# D1H.pdf register map
Vendor: Allwinner; Series: D1H.pdf; File version: 0.1
CPU: XuanTie C906 RISC-V CPU 0, little endian, MPU, FPU, double-precision FPU, 0 interrupt priority bits
Registers are 32-bit, read-write, reset 0x0 unless marked. A register's access mark holds for its fields unless they carry their own. Offsets are from the block's base; [hi:lo] are bit positions; {n}, {i} and the like mark numbered series; 'fields as' and 'values as' point back to an identical list.

## GPIO
Base 0x02000000
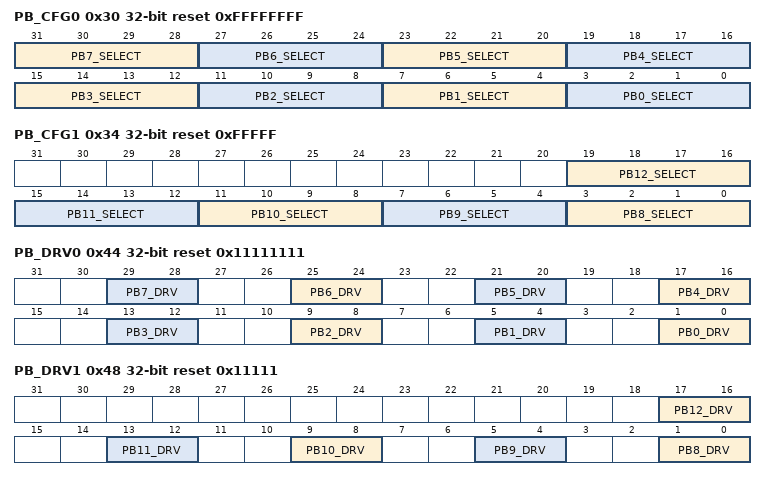
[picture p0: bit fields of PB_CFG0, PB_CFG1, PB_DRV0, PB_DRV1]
0x30 PB_CFG0 reset 0xFFFFFFFF — PB Configure Register 0
  [31:28] PB7_SELECT — PB7 Select 0000:Input 0001:Output 0010:LCD0-D17 0011:I2S2-MCLK 0100:TWI3-SDA 0101:IR-RX 0110:LCD0-D23 0111:UART3-RX 1000:CPUBIST1 1001:Reserved 1110:PB-EINT7 1111:IO Disable
  [27:24] PB6_SELECT — PB6 Select 0000:Input 0001:Output 0010:LCD0-D16 0011:I2S2-LRCK 0100:TWI3-SCK 0101:PWM1 0110:LCD0-D22 0111:UART3-TX 1000:CPUBIST0 1001:Reserved 1110:PB-EINT6 1111:IO Disable
  [23:20] PB5_SELECT — PB5 Select 0000:Input 0001:Output 0010:LCD0-D9 0011:I2S2-BCLK 0100:TWI1-SDA 0101:PWM0 0110:LCD0-D21 0111:UART5-RX 1000:Reserved 1001:Reserved 1110:PB-EINT5 1111:IO Disable
  [19:16] PB4_SELECT — PB4 Select 0000:Input 0001:Output 0010:LCD0-D8 0011:I2S2-DOUT0 0100:TWI1-SCK 0101:I2S2-DIN1 0110:LCD0-D20 0111:UART5-TX 1000:Reserved 1001:Reserved 1110:PB-EINT4 1111:IO Disable
  [15:12] PB3_SELECT — PB3 Select 0000:Input 0001:Output 0010:LCD0-D1 0011:I2S2-DOUT1 0100:TWI0-SCK 0101:I2S2-DIN0 0110:LCD0-D19 0111:UART4-RX 1000:Reserved 1001:Reserved 1110:PB-EINT3 1111:IO Disable
  [11:8] PB2_SELECT — PB2 Select 0000:Input 0001:Output 0010:LCD0-D0 0011:I2S2-DOUT2 0100:TWI0-SDA 0101:I2S2-DIN2 0110:LCD0-D18 0111:UART4-TX 1000:Reserved 1001:Reserved 1110:PB-EINT2 1111:IO Disable
  [7:4] PB1_SELECT — PB1 Select 0000:Input 0001:Output 0010:PWM4 0011:I2S2-DOUT3 0100:TWI2-SDA 0101:I2S2-DIN3 0110:UART0-RX 0111:UART2-RX 1000:IR-RX 1001:Reserved 1110:PB-EINT1 1111:IO Disable
  [3:0] PB0_SELECT — PB0 Select 0000:Input 0001:Output 0010:PWM3 0011:IR-TX 0100:TWI2-SCK 0101:SPI1-WP/DBI-TE 0110:UART0-TX 0111:UART2-TX 1000:OWA-OUT 1001:Reserved 1110:PB-EINT0 1111:IO Disable
0x34 PB_CFG1 reset 0xFFFFF — PB Configure Register 1
  [19:16] PB12_SELECT — PB12 Select 0000:Input 0001:Output 0010:DMIC-CLK 0011:PWM0 0100: Reserved 0101:SPI1-CS/DBI-CSX 0110:CLK-FANOUT2 0111:IR-RX 1000:Reserved 1001:Reserved 1110:PB-EINT12 1111:IO Disable
    5=SPI1_minus_CS_slash_DBI_minus_CSX (SPI1-CS/DBI-CSX); 6=CLK_minus_FANOUT2 (CLK-FANOUT2); 7=IR_minus_RX (IR-RX); 14=PB_minus_EINT12 (PB-EINT12); 15=IO (IO Disable)
  [15:12] PB11_SELECT — PB11 Select 0000:Input 0001:Output 0010:DMIC-DATA0 0011:PWM2 0100:TWI0-SDA 0101:SPI1-CLK/DBI-SCLK 0110:CLK-FANOUT1 0111:UART1-CTS 1000:Reserved 1001:Reserved 1110:PB-EINT11 1111:IO Disable
  [11:8] PB10_SELECT — PB10 Select 0000:Input 0001:Output 0010:DMIC-DATA1 0011:PWM7 0100:TWI0-SCK 0101:SPI1-MOSI/DBI-SDO 0110:CLK-FANOUT0 0111:UART1-RTS 1000:Reserved 1001:Reserved 1110:PB-EINT10 1111:IO Disable
  [7:4] PB9_SELECT — PB9 Select 0000:Input 0001:Output 0010:DMIC-DATA2 0011:PWM6 0100:TWI2-SDA 0101:SPI1-MISO/DBI-SDI/DBI-TE/DBI-DCX 0110:UART0-RX 0111:UART1-RX 1000:Reserved 1001:Reserved 1110:PB-EINT9 1111:IO Disable
  [3:0] PB8_SELECT — PB8 Select 0000:Input 0001:Output 0010:DMIC-DATA3 0011:PWM5 0100:TWI2-SCK 0101:SPI1-HOLD/DBI-DCX/DBI-WRX 0110:UART0-TX 0111:UART1-TX 1000:Reserved 1001:Reserved 1110:PB-EINT8 1111:IO Disable
0x40 PB_DAT — PB Data Register
  [12:0] PB_DAT — If the port is configured as the input function, the corresponding bit is the pin state. If the port is configured as the output function, the pin state is the same as the corresponding bit. The read bit value is the value set up by software. If the port is configured as a functional pin, the undefined value will be read.
0x44 PB_DRV0 reset 0x11111111 — PB Multi_Driving Register 0
  [all] fields
    {v}=Level_{v} (v=0..3)
  [4n+1:4n] PB{n}_DRV (n=0..7) — PB{n} Multi_Driving Select 00: Level 0 01: Level 1 10: Level 2 11: Level 3
0x48 PB_DRV1 reset 0x11111 — PB Multi_Driving Register 1
  [all] fields
    {v}=Level_{v} (v=0..3)
  [4n-31:4n-32] PB{n}_DRV (n=8..12) — PB{n} Multi_Driving Select 00: Level 0 01: Level 1 10: Level 2 11: Level 3
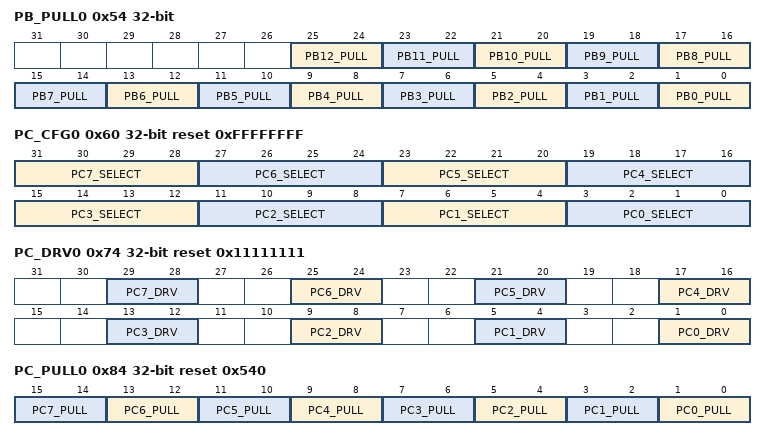
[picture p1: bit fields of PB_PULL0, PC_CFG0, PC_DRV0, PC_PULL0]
0x54 PB_PULL0 — PB Pull Register 0
  [all] fields
    0=Pull_up_slash_down_disable (Pull_up/down disable); 1=Pull_up; 2=Pull_down
  [2n+1:2n] PB{n}_PULL (n=0..12) — PB{n} Pull_up or down Select 00: Pull_up/down disable 01: Pull_up 10: Pull_down 11: Reserved
0x60 PC_CFG0 reset 0xFFFFFFFF — PC Configure Register 0
  [31:28] PC7_SELECT — PC7 Select 0000:Input 0001:Output 0010:SPI0-HOLD 0011:SDC2-D3 0100:UART3-RX 0101:TWI3-SDA 0110:TCON-TRIG 0111:Reserved 1000:Reserved 1001:Reserved 1110:PC-EINT7 1111:IO Disable
  [27:24] PC6_SELECT — PC6 Select 0000:Input 0001:Output 0010:SPI0-WP 0011:SDC2-D0 0100:UART3-TX 0101:TWI3-SCK 0110:DBG-CLK 0111:Reserved 1000:Reserved 1001:Reserved 1110:PC-EINT6 1111:IO Disable
  [23:20] PC5_SELECT — PC5 Select 0000:Input 0001:Output 0010:SPI0-MISO 0011:SDC2-D1 0100:BOOT-SEL1 0101:Reserved 0110:Reserved 0111:Reserved 1000:Reserved 1001:Reserved 1110:PC-EINT5 1111:IO Disable
  [19:16] PC4_SELECT — PC4 Select 0000:Input 0001:Output 0010:SPI0-MOSI 0011:SDC2-D2 0100:BOOT-SEL0 0101:Reserved 0110:Reserved 0111:Reserved 1000:Reserved 1001:Reserved 1110:PC-EINT4 1111:IO Disable
  [15:12] PC3_SELECT — PC3 Select 0000:Input 0001:Output 0010:SPI0-CS0 0011:SDC2-CMD 0100:Reserved 0101:Reserved 0110:Reserved 0111:Reserved 1000:Reserved 1001:Reserved 1110:PC-EINT3 1111:IO Disable
  [11:8] PC2_SELECT — PC2 Select 0000:Input 0001:Output 0010:SPI0-CLK 0011:SDC2-CLK 0100:Reserved 0101:Reserved 0110:Reserved 0111:Reserved 1000:Reserved 1001:Reserved 1110:PC-EINT2 1111:IO Disable
  [7:4] PC1_SELECT — PC1 Select. 0000:Input 0001:Output 0010:UART2-RX 0011:TWI2-SDA 0100:Reserved 0101:Reserved 0110:Reserved 0111:Reserved 1000:Reserved 1001:Reserved 1110:PC-EINT1 1111:IO Disable
  [3:0] PC0_SELECT — PC0 Select 0000:Input 0001:Output 0010:UART2-TX 0011:TWI2-SCK 0100:LEDC-DO 0101:Reserved 0110:Reserved 0111:Reserved 1000:Reserved 1001:Reserved 1110:PC-EINT0 1111:IO Disable
0x70 PC_DAT — PC Data Register
  [7:0] PC_DAT — If the port is configured as the input function, the corresponding bit is the pin state. If the port is configured as the output function, the pin state is the same as the corresponding bit. The read bit value is the value set up by software. If the port is configured as a functional pin, the undefined value will be read.
0x74 PC_DRV0 reset 0x11111111 — PC Multi_Driving Register 0
  [all] fields
    {v}=Level_{v} (v=0..3)
  [4n+1:4n] PC{n}_DRV (n=0..7) — PC{n} Multi_Driving Select 00: Level 0 01: Level 1 10: Level 2 11: Level 3
0x84 PC_PULL0 reset 0x540 — PC Pull Register 0
  [all] fields
    values as the fields of PB_PULL0
  [2n+1:2n] PC{n}_PULL (n=0..7) — PC{n} Pull_up/down Select 00: Pull_up/down disable 01: Pull_up 10: Pull_down 11: Reserved
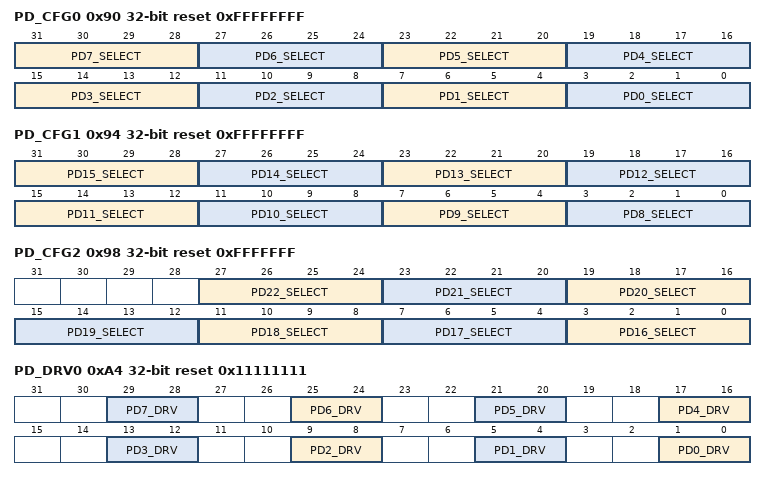
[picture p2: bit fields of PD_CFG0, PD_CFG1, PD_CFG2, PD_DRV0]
0x90 PD_CFG0 reset 0xFFFFFFFF — PD Configure Register 0
  [31:28] PD7_SELECT — PD7 Select 0000:Input 0001:Output 0010:LCD0-D11 0011:LVDS0-CKN 0100:DSI-D2N 0101:UART4-TX 0110:Reserved 0111:Reserved 1000:Reserved 1001:Reserved 1110:PD-EINT7 1111:IO Disable
  [27:24] PD6_SELECT — PD6 Select 0000:Input 0001:Output 0010:LCD0-D10 0011:LVDS0-CKP 0100:DSI-D2P 0101:UART5-RX 0110:Reserved 0111:Reserved 1000:Reserved 1001:Reserved 1110:PD-EINT6 1111:IO Disable
  [23:20] PD5_SELECT — PD5 Select 0000:Input 0001:Output 0010:LCD0-D7 0011:LVDS0-V2N 0100:DSI-CKN 0101:UART5-TX 0110:Reserved 0111:Reserved 1000:Reserved 1001:Reserved 1110:PD-EINT5 1111:IO Disable
  [19:16] PD4_SELECT — PD4 Select 0000:Input 0001:Output 0010:LCD0-D6 0011:LVDS0-V2P 0100:DSI-CKP 0101:UART2-CTS 0110:Reserved 0111:Reserved 1000:Reserved 1001:Reserved 1110:PD-EINT4 1111:IO Disable
  [15:12] PD3_SELECT — PD3 Select 0000:Input 0001:Output 0010:LCD0-D5 0011:LVDS0-V1N 0100:DSI-D1N 0101:UART2-RTS 0110:Reserved 0111:Reserved 1000:Reserved 1001:Reserved 1110:PD-EINT3 1111:IO Disable
  [11:8] PD2_SELECT — PD2 Select 0000:Input 0001:Output 0010:LCD0-D4 0011:LVDS0-V1P 0100:DSI-D1P 0101:UART2-RX 0110:Reserved 0111:Reserved 1000:Reserved 1001:Reserved 1110:PD-EINT2 1111:IO Disable
  [7:4] PD1_SELECT — PD1 Select 0000:Input 0001:Output 0010:LCD0-D3 0011:LVDS0-V0N 0100:DSI-D0N 0101:UART2-TX 0110:Reserved 0111:Reserved 1000:Reserved 1001:Reserved 1110:PD-EINT1 1111:IO Disable
  [3:0] PD0_SELECT — PD0 Select 0000:Input 0001:Output 0010:LCD0-D2 0011:LVDS0-V0P 0100:DSI-D0P 0101:TWI0-SCK 0110:Reserved 0111:Reserved 1000:Reserved 1001:Reserved 1110:PD-EINT0 1111:IO Disable
0x94 PD_CFG1 reset 0xFFFFFFFF — PD Configure Register 1
  [31:28] PD15_SELECT — PD15 Select 0000:Input 0001:Output 0010:LCD0-D21 0011:LVDS1-V2N 0100:SPI1-WP/DBI-TE 0101:IR-RX 0110:Reserved 0111:Reserved 1000:Reserved 1001:Reserved 1110:PD-EINT15 1111:IO Disable
  [27:24] PD14_SELECT — PD14 Select 0000:Input 0001:Output 0010:LCD0-D20 0011:LVDS1-V2P 0100:SPI1-HOLD/DBI-DCX/DBI-WRX 0101:UART3-CTS 0110:Reserved 0111:Reserved 1000:Reserved 1001:Reserved 1110:PD-EINT14 1111:IO Disable
  [23:20] PD13_SELECT — PD13 Select 0000:Input 0001:Output 0010:LCD0-D19 0011:LVDS1-V1N 0100:SPI1-MISO/DBI-SDI/DBI-TE/DBI-DCX 0101:UART3-RTS 0110:Reserved 0111:Reserved 1000:Reserved 1001:Reserved 1110:PD-EINT13 1111:IO Disable
  [19:16] PD12_SELECT — PD12 Select 0000:Input 0001:Output 0010:LCD0-D18 0011:LVDS1-V1P 0100:SPI1-MOSI/DBI-SDO 0101:TWI0-SDA 0110:Reserved 0111:Reserved 1000:Reserved 1001:Reserved 1110:PD-EINT12 1111:IO Disable
  [15:12] PD11_SELECT — PD11 Select 0000:Input 0001:Output 0010:LCD0-D15 0011:LVDS1-V0N 0100:SPI1-CLK/DBI-SCLK 0101:UART3-RX 0110:Reserved 0111:Reserved 1000:Reserved 1001:Reserved 1110:PD-EINT11 1111:IO Disable
  [11:8] PD10_SELECT — PD10 Select 0000:Input 0001:Output 0010:LCD0-D14 0011:LVDS1-V0P 0100:SPI1-CS/DBI-CSX 0101:UART3-TX 0110:Reserved 0111:Reserved 1000:Reserved 1001:Reserved 1110:PD-EINT10 1111:IO Disable
  [7:4] PD9_SELECT — PD9 Select 0000:Input 0001:Output 0010:LCD0-D13 0011:LVDS0-V3N 0100:DSI-D3N 0101:PWM6 0110:Reserved 0111:Reserved 1000:Reserved 1001:Reserved 1110:PD-EINT9 1111:IO Disable
  [3:0] PD8_SELECT — PD8 Select 0000:Input 0001:Output 0010:LCD0-D12 0011:LVDS0-V3P 0100:DSI-D3P 0101:UART4-RX 0110:Reserved 0111:Reserved 1000:Reserved 1001:Reserved 1110:PD-EINT8 1111:IO Disable
0x98 PD_CFG2 reset 0xFFFFFFF — PD Configure Register 2
  [27:24] PD22_SELECT — PD22 Select 0000:Input 0001:Output 0010:OWA-OUT 0011:IR-RX 0100:UART1-RX 0101:PWM7 0110:Reserved 0111:Reserved 1000:Reserved 1001:Reserved 1110:PD-EINT22 1111:IO Disable
  [23:20] PD21_SELECT — PD21 Select 0000:Input 0001:Output 0010:LCD0-VSYNC 0011:TWI2-SDA 0100:UART1-TX 0101:PWM5 0110:Reserved 0111:Reserved 1000:Reserved 1001:Reserved 1110:PD-EINT21 1111:IO Disable
  [19:16] PD20_SELECT — PD20 Select 0000:Input 0001:Output 0010:LCD0-HSYNC 0011:TWI2-SCK 0100:DMIC-CLK 0101:PWM4 0110:Reserved 0111:Reserved 1000:Reserved 1001:Reserved 1110:PD-EINT20 1111:IO Disable
  [15:12] PD19_SELECT — PD19 Select 0000:Input 0001:Output 0010:LCD0-DE 0011:LVDS1-V3N 0100:DMIC-DATA0 0101:PWM3 0110:Reserved 0111:Reserved 1000:Reserved 1001:Reserved 1110:PD-EINT19 1111:IO Disable
  [11:8] PD18_SELECT — PD18 Select 0000:Input 0001:Output 0010:LCD0-CLK 0011:LVDS1-V3P 0100:DMIC-DATA1 0101:PWM2 0110:Reserved 0111:Reserved 1000:Reserved 1001:Reserved 1110:PD-EINT18 1111:IO Disable
  [7:4] PD17_SELECT — PD17 Select. 0000:Input 0001:Output 0010:LCD0-D23 0011:LVDS1-CKN 0100:DMIC-DATA2 0101:PWM1 0110:Reserved 0111:Reserved 1000:Reserved 1001:Reserved 1110:PD-EINT17 1111:IO Disable
  [3:0] PD16_SELECT — PD16 Select 0000:Input 0001:Output 0010:LCD0-D22 0011:LVDS1-CKP 0100:DMIC-DATA3 0101:PWM0 0110:Reserved 0111:Reserved 1000:Reserved 1001:Reserved 1110:PD-EINT16 1111:IO Disable
0xA0 PD_DAT — PD Data Register
  [22:0] PD_DAT — PD Data If the port is configured as the input function, the corresponding bit is the pin state. If the port is configured as the output function, the pin state is the same as the corresponding bit. The read bit value is the value set up by software. If the port is configured as a functional pin, the undefined value will be read.
0xA4 PD_DRV0 reset 0x11111111 — PD Multi_Driving Register 0
  [all] fields
    {v}=Level_{v} (v=0..3)
  [4n+1:4n] PD{n}_DRV (n=0..7) — PD{n} Multi_Driving Select. 00: Level 0 01: Level 1 10: Level 2 11: Level 3
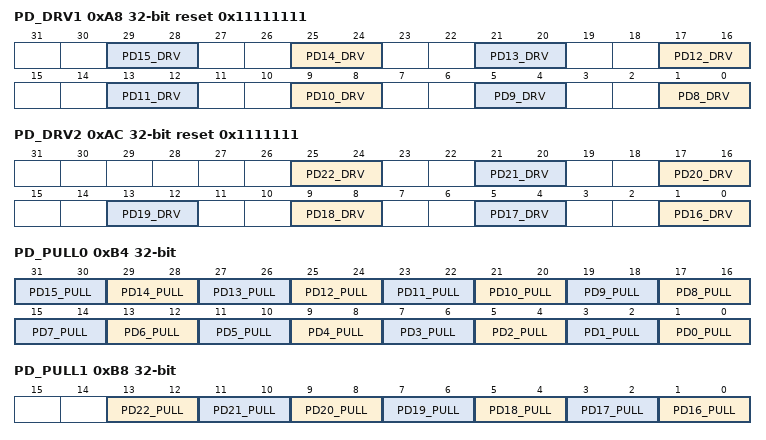
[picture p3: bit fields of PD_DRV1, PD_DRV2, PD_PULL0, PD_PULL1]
0xA8 PD_DRV1 reset 0x11111111 — PD Multi_Driving Register 1
  [all] fields
    {v}=Level_{v} (v=0..3)
  [4n-31:4n-32] PD{n}_DRV (n=8..15) — PD{n} Multi_Driving Select. 00: Level 0 01: Level 1 10: Level 2 11: Level 3
0xAC PD_DRV2 reset 0x1111111 — PD Multi_Driving Register 2
  [all] fields
    {v}=Level_{v} (v=0..3)
  [4n-63:4n-64] PD{n}_DRV (n=16..22) — PD{n} Multi_Driving Select. 00: Level 0 01: Level 1 10: Level 2 11: Level 3
0xB4 PD_PULL0 — PD Pull Register 0
  [all] fields
    values as the fields of PB_PULL0
  [2n+1:2n] PD{n}_PULL (n=0..15) — PD{n} Pull_up or down Select. 00: Pull_up/down disable 01: Pull_up 10: Pull_down 11: Reserved
0xB8 PD_PULL1 — PD Pull Register 1
  [all] fields
    values as the fields of PB_PULL0
  [2n-31:2n-32] PD{n}_PULL (n=16..22) — PD{n} Pull_up or down Select. 00: Pull_up/down disable 01: Pull_up 10: Pull_down 11: Reserved
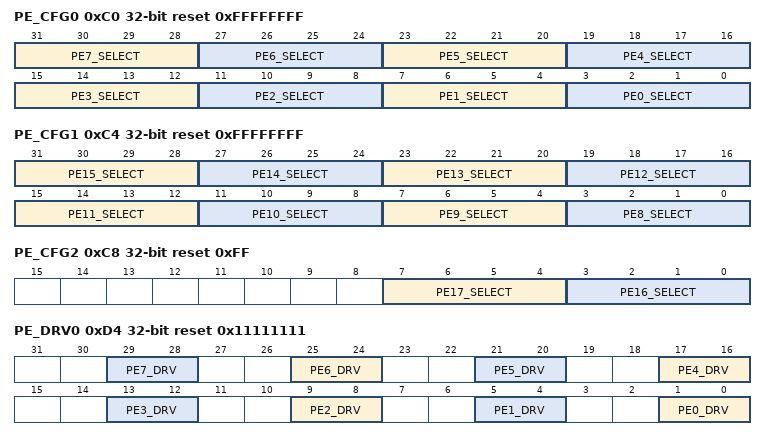
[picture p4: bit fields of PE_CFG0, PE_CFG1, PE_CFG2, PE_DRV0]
0xC0 PE_CFG0 reset 0xFFFFFFFF — PE Configure Register 0
  [31:28] PE7_SELECT — PE7 Select 0000:Input 0001:Output 0010:NCSI0-D3 0011:UART5-RX 0100:TWI3-SDA 0101:OWA-OUT 0110:D-JTAG-CK 0111:R-JTAG-CK 1000:RGMII-CLKIN/RMII-RXER 1001:Reserved 1110:PE-EINT7 1111:IO Disable
  [27:24] PE6_SELECT — PE6 Select 0000:Input 0001:Output 0010:NCSI0-D2 0011:UART5-TX 0100:TWI3-SCK 0101: Reserved 0110:D-JTAG-DO 0111:R-JTAG-DO 1000:RMII-TXCTRL/RMII-TXEN 1001:Reserved 1110:PE-EINT6 1111:IO Disable
  [23:20] PE5_SELECT — PE5 Select 0000:Input 0001:Output 0010:NCSI0-D1 0011:UART4-RX 0100:TWI2-SDA 0101:LEDC-DO 0110:D-JTAG-DI 0111:R-JTAG-DI 1000:RGMII-TXD1/RMII-TXD1 1001:Reserved 1110:PE-EINT5 1111:IO Disable
  [19:16] PE4_SELECT — PE4 Select 0000:Input 0001:Output 0010:NCSI0-D0 0011:UART4-TX 0100:TWI2-SCK 0101:CLK-FANOUT2 0110:D-JTAG-MS 0111:R-JTAG-MS 1000:RGMII-TXD0/RMII-TXD0 1001:Reserved 1110:PE-EINT4 1111:IO Disable
  [15:12] PE3_SELECT — PE3 Select 0000:Input 0001:Output 0010:NCSI0-MCLK 0011:UART2-RX 0100:TWI0-SDA 0101:CLK-FANOUT1 0110:UART0-RX 0111:Reserved 1000:RGMII-TXCK/RMII-TXCK 1001:Reserved 1110:PE-EINT3 1111:IO Disable
  [11:8] PE2_SELECT — PE2 Select 0000:Input 0001:Output 0010:NCSI0-PCLK 0011:UART2-TX 0100:TWI0-SCK 0101:CLK-FANOUT0 0110:UART0-TX 0111:Reserved 1000:RGMII-RXD1/RMII-RXD1 1001:Reserved 1110:PE-EINT2 1111:IO Disable
  [7:4] PE1_SELECT — PE1 Select 0000:Input 0001:Output 0010:NCSI0-VSYNC 0011:UART2-CTS 0100:TWI1-SDA 0101:LCD0-VSYNC 0110:Reserved 0111:Reserved 1000:RGMII-RXD0/RMII-RXD0 1001:Reserved 1110:PE-EINT1 1111:IO Disable
  [3:0] PE0_SELECT — PE0 Select 0000:Input 0001:Output 0010:NCSI0-HSYNC 0011:UART2-RTS 0100:TWI1-SCK 0101:LCD0-HSYNC 0110:Reserved 0111:Reserved 1000:RGMII-RXCTRL/RMII-CRS-DV 1001:Reserved 1110:PE-EINT0 1111:IO Disable
0xC4 PE_CFG1 reset 0xFFFFFFFF — PE Configure Register 1
  [31:28] PE15_SELECT — PE15 Select 0000:Input 0001:Output 0010:TWI1-SDA 0011:D-JTAG-DI 0100:PWM6 0101:I2S0-LRCK 0110:DMIC-DATA1 0111:Reserved 1000:RGMII-RXCK 1001:Reserved 1110:PE-EINT15 1111:IO Disable
  [27:24] PE14_SELECT — PE14 Select 0000:Input 0001:Output 0010:TWI1-SCK 0011:D-JTAG-MS 0100:I2S0-DOUT1 0101:I2S0-DIN0 0110:DMIC-DATA2 0111:Reserved 1000:RGMII-RXD3 1001:Reserved 1110:PE-EINT14 1111:IO Disable
  [23:20] PE13_SELECT — PE13 Select 0000:Input 0001:Output 0010:TWI2-SDA 0011:PWM5 0100:I2S0-DOUT0 0101:I2S0-DIN1 0110:DMIC-DATA3 0111:Reserved 1000:RGMII-RXD2 1001:Reserved 1110:PE-EINT13 1111:IO Disable
  [19:16] PE12_SELECT — PE12 Select 0000:Input 0001:Output 0010:TWI2-SCK 0011:NCSI0-FIELD 0100:I2S0-DOUT2 0101:I2S0-DIN2 0110:Reserved 0111:Reserved 1000:RGMII-TXD3 1001:Reserved 1110:PE-EINT12 1111:IO Disable
  [15:12] PE11_SELECT — PE11 Select 0000:Input 0001:Output 0010:NCSI0-D7 0011:UART1-RX 0100:I2S0-DOUT3 0101:I2S0-DIN3 0110:Reserved 0111:Reserved 1000:RGMII-TXD2 1001:Reserved 1110:PE-EINT11 1111:IO Disable
  [11:8] PE10_SELECT — PE10 Select 0000:Input 0001:Output 0010:NCSI0-D6 0011:UART1-TX 0100:PWM4 0101:IR-RX 0110:Reserved 0111:Reserved 1000:EPHY-25M 1001:Reserved 1110:PE-EINT10 1111:IO Disable
  [7:4] PE9_SELECT — PE9 Select 0000:Input 0001:Output 0010:NCSI0-D5 0011:UART1-CTS 0100:PWM3 0101:UART3-RX 0110:Reserved 0111:Reserved 1000:MDIO 1001:Reserved 1110:PE-EINT9 1111:IO Disable
  [3:0] PE8_SELECT — PE8 Select 0000:Input 0001:Output 0010:NCSI0-D4 0011:UART1-RTS 0100:PWM2 0101:UART3-TX 0110:Reserved 0111:Reserved 1000:MDC 1001:Reserved 1110:PE-EINT8 1111:IO Disable
0xC8 PE_CFG2 reset 0xFF
  [7:4] PE17_SELECT — PE17 Select 0000:Input 0001:Output 0010:TWI3-SDA 0011:D-JTAG-CK 0100:IR-TX 0101:I2S0-MCLK 0110:DMIC-CLK 0111:Reserved 1000:Reserved 1001:Reserved 1110:PE-EINT17 1111:IO Disable
  [3:0] PE16_SELECT — PE16 Select 0000:Input 0001:Output 0010:TWI3-SCK 0011:D-JTAG-DO 0100:PWM7 0101:I2S0-BCLK 0110:DMIC-DATA0 0111:Reserved 1000:Reserved 1001:Reserved 1110:PE-EINT16 1111:IO Disable
0xD0 PE_DAT — PE Data Register
  [17:0] PE_DAT — PE Data If the port is configured as input, the corresponding bit is the pin state. If the port is configured as output, the pin state is the same as the corresponding bit. The read bit value is the value setup by software. If the port is configured as functional pin, the undefined value will be read.
0xD4 PE_DRV0 reset 0x11111111 — PE Multi_Driving Register 0
  [all] fields
    {v}=Level_{v} (v=0..3)
  [4n+1:4n] PE{n}_DRV (n=0..7) — PE{n} Multi_Driving Select 00: Level 0 01: Level 1 10: Level 2 11: Level 3
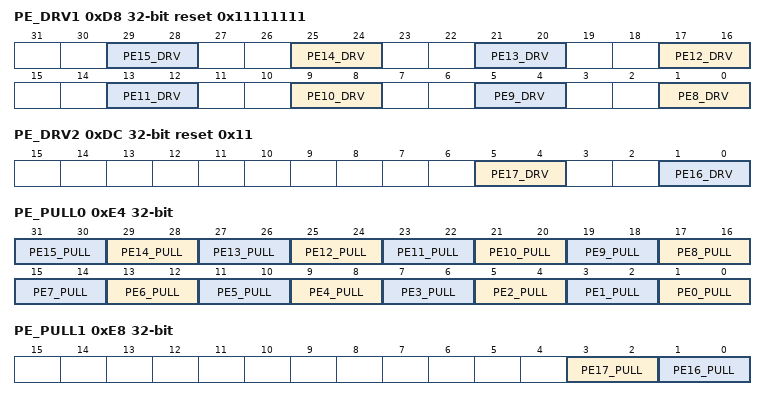
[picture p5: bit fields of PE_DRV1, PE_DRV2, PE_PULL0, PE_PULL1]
0xD8 PE_DRV1 reset 0x11111111 — PE Multi_Driving Register 1
  [all] fields
    {v}=Level_{v} (v=0..3)
  [4n-31:4n-32] PE{n}_DRV (n=8..15) — PE{n} Multi_Driving Select 00: Level 0 01: Level 1 10: Level 2 11: Level 3
0xDC PE_DRV2 reset 0x11
  [5:4] PE17_DRV — PE17 Multi_Driving Select 00: Level 0 01: Level 1 10: Level 2 11: Level 3
    {v}=Level_{v} (v=0..3)
  [1:0] PE16_DRV — PE16 Multi_Driving Select 00: Level 0 01: Level 1 10: Level 2 11: Level 3
    {v}=Level_{v} (v=0..3)
0xE4 PE_PULL0 — PE Pull Register 0
  [all] fields
    values as the fields of PB_PULL0
  [2n+1:2n] PE{n}_PULL (n=0..15) — PE{n} Pull_up or down Select 00: Pull_up/down disable 01: Pull_up 10: Pull_down 11: Reserved
0xE8 PE_PULL1
  [3:2] PE17_PULL — PE17 Pull_up or down Select 00: Pull_up/down disable 01: Pull_up 10: Pull_down 11: Reserved
    values as the fields of PB_PULL0
  [1:0] PE16_PULL — PE16 Pull_up or down Select 00: Pull_up/down disable 01: Pull_up 10: Pull_down 11: Reserved
    values as the fields of PB_PULL0
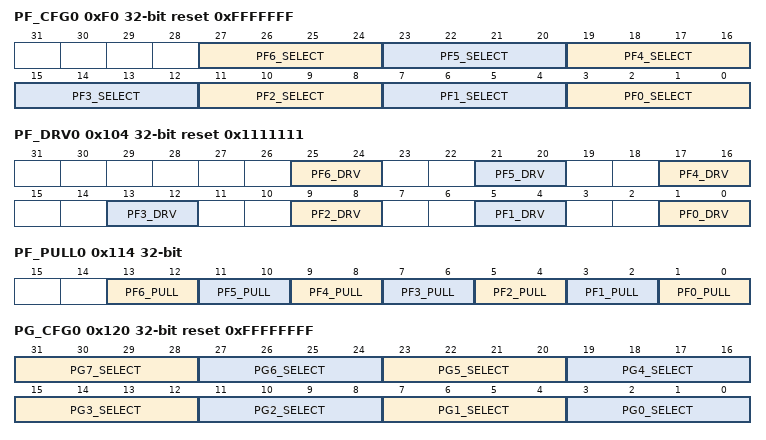
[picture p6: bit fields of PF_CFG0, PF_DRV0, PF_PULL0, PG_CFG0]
0xF0 PF_CFG0 reset 0xFFFFFFF — PF Configure Register 0
  [27:24] PF6_SELECT — PF6 Select 0000:Input 0001:Output 0010:Reserved 0011:OWA-OUT 0100:IR-RX 0101:I2S2-MCLK 0110:PWM5 0111:Reserved 1000:Reserved 1001:Reserved 1110:PF-EINT6 1111:IO Disable
  [23:20] PF5_SELECT — PF5 Select 0000:Input 0001:Output 0010:SDC0-D2 0011:Reserved 0100:R-JTAG-CK 0101:I2S2-LRCK 0110:Reserved 0111:Reserved 1000:Reserved 1001:Reserved 1110:PF-EINT5 1111:IO Disable
  [19:16] PF4_SELECT — PF4 Select 0000:Input 0001:Output 0010:SDC0-D3 0011:UART0-RX 0100:TWI0-SDA 0101:PWM6 0110:IR-TX 0111:Reserved 1000:Reserved 1001:Reserved 1110:PF-EINT4 1111:IO Disable
  [15:12] PF3_SELECT — PF3 Select 0000:Input 0001:Output 0010:SDC0-CMD 0011:Reserved 0100:R-JTAG-DO 0101:I2S2-BCLK 0110:Reserved 0111:Reserved 1000:Reserved 1001:Reserved 1110:PF-EINT3 1111:IO Disable
  [11:8] PF2_SELECT — PF2 Select 0000:Input 0001:Output 0010:SDC0-CLK 0011:UART0-TX 0100:TWI0-SCK 0101: Reserved 0110: Reserved 0111: Reserved 1000:Reserved 1001:Reserved 1110:PF-EINT2 1111:IO Disable
    14=PF_minus_EINT2 (PF-EINT2); 15=IO (IO Disable)
  [7:4] PF1_SELECT — PF1 Select 0000:Input 0001:Output 0010:SDC0-D0 0011:Reserved 0100:R-JTAG-DI 0101:I2S2-DOUT0 0110:I2S2-DIN1 0111:Reserved 1000:Reserved 1001:Reserved 1110:PF-EINT1 1111:IO Disable
  [3:0] PF0_SELECT — PF0 Select 0000:Input 0001:Output 0010:SDC0-D1 0011:Reserved 0100:R-JTAG-MS 0101:I2S2-DOUT1 0110:I2S2-DIN0 0111:Reserved 1000:Reserved 1001:Reserved 1110:PF-EINT0 1111:IO Disable
0x100 PF_DAT — PF Data Register
  [6:0] PF_DAT — PF Data If the port is configured as input, the corresponding bit is the pin state. If the port is configured as output, the pin state is the same as the corresponding bit. The read bit value is the value setup by software. If the port is configured as functional pin, the undefined value will be read.
0x104 PF_DRV0 reset 0x1111111 — PF Multi_Driving Register 0
  [all] fields
    {v}=Level_{v} (v=0..3)
  [4n+1:4n] PF{n}_DRV (n=0..6) — PF{n} Multi_Driving Select 00: Level 0 01: Level 1 10: Level 2 11: Level 3
0x114 PF_PULL0 — PF Pull Register 0
  [all] fields
    values as the fields of PB_PULL0
  [2n+1:2n] PF{n}_PULL (n=0..6) — PF{n} Pull_up or down Select 00: Pull_up/down disable 01: Pull_up 10: Pull_down 11: Reserved
0x120 PG_CFG0 reset 0xFFFFFFFF — PG Configure Register 0
  [31:28] PG7_SELECT — PG7 Select 0000:Input 0001:Output 0010:UART1-RX 0011:TWI2-SDA 0100:RGMII-TXD3 0101: Reserved 0110:Reserved 0111:Reserved 1000:Reserved 1001:Reserved 1110:PG-EINT7 1111:IO Disable
  [27:24] PG6_SELECT — PG6 Select 0000:Input 0001:Output 0010:UART1-TX 0011:TWI2-SCK 0100:RGMII-TXD2 0101:PWM1 0110:Reserved 0111:Reserved 1000:Reserved 1001:Reserved 1110:PG-EINT6 1111:IO Disable
  [23:20] PG5_SELECT — PG5 Select 0000:Input 0001:Output 0010:SDC1-D3 0011:UART5-RX 0100:RGMII-TXD1/RMII-TXD1 0101:PWM4 0110:Reserved 0111:Reserved 1000:Reserved 1001:Reserved 1110:PG-EINT5 1111:IO Disable
  [19:16] PG4_SELECT — PG4 Select 0000:Input 0001:Output 0010:SDC1-D2 0011:UART5-TX 0100:RGMII-TXD0/RMII-TXD0 0101:PWM5 0110:Reserved 0111:Reserved 1000:Reserved 1001:Reserved 1110:PG-EINT4 1111:IO Disable
  [15:12] PG3_SELECT — PG3 Select 0000:Input 0001:Output 0010:SDC1-D1 0011:UART3-CTS 0100:RGMII-TXCK/RMII-TXCK 0101:UART4-RX 0110:Reserved 0111:Reserved 1000:Reserved 1001:Reserved 1110:PG-EINT3 1111:IO Disable
  [11:8] PG2_SELECT — PG2 Select 0000:Input 0001:Output 0010:SDC1-D0 0011:UART3-RTS 0100:RGMII-RXD1/RMII-RXD1 0101:UART4-TX 0110:Reserved 0111:Reserved 1000:Reserved 1001:Reserved 1110:PG-EINT2 1111:IO Disable
  [7:4] PG1_SELECT — PG1 Select 0000:Input 0001:Output 0010:SDC1-CMD 0011:UART3-RX 0100:RGMII-RXD0/RMII-RXD0 0101:PWM6 0110:Reserved 0111:Reserved 1000:Reserved 1001:Reserved 1110:PG-EINT1 1111:IO Disable
  [3:0] PG0_SELECT — PG0 Select 0000:Input 0001:Output 0010:SDC1-CLK 0011:UART3-TX 0100:RGMII-RXCTRL/RMII-CRS-DV 0101:PWM7 0110:Reserved 0111:Reserved 1000:Reserved 1001:Reserved 1110:PG-EINT0 1111:IO Disable
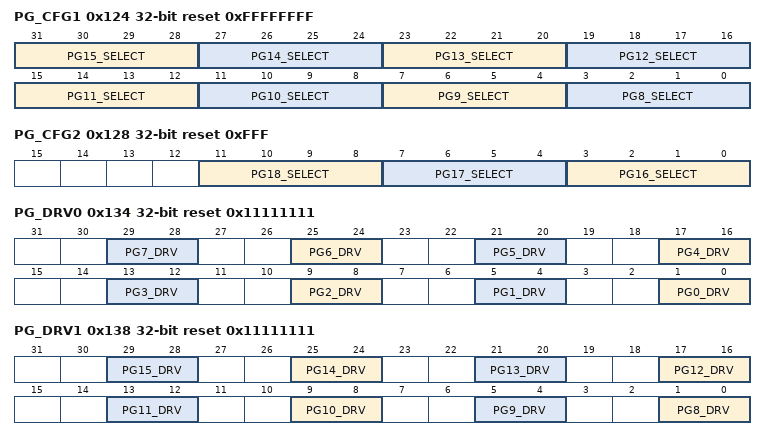
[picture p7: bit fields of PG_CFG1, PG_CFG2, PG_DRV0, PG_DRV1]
0x124 PG_CFG1 reset 0xFFFFFFFF — PG Configure Register 1
  [31:28] PG15_SELECT — PG15 Select 0000:Input 0001:Output 0010:I2S1-DOUT0 0011:TWI2-SDA 0100:MDIO 0101:I2S1-DIN1 0110:SPI0-HOLD 0111:UART1-CTS 1000:Reserved 1001:Reserved 1110:PG-EINT15 1111:IO Disable
  [27:24] PG14_SELECT — PG14 Select 0000:Input 0001:Output 0010:I2S1-DIN0 0011:TWI2-SCK 0100:MDC 0101:I2S1-DOUT1 0110:SPI0-WP 0111:UART1-RTS 1000:Reserved 1001:Reserved 1110:PG-EINT14 1111:IO Disable
  [23:20] PG13_SELECT — PG13 Select 0000:Input 0001:Output 0010:I2S1-BCLK 0011:TWI0-SDA 0100:RGMII-CLKIN/RMII-RXER 0101:PWM2 0110:LEDC-DO 0111:UART1-RX 1000:Reserved 1001:Reserved 1110:PG-EINT13 1111:IO Disable
  [19:16] PG12_SELECT — PG12 Select 0000:Input 0001:Output 0010:I2S1-LRCK 0011:TWI0-SCK 0100:RGMII-TXCTRL/RMII-TXEN 0101:CLK-FANOUT2 0110:PWM0 0111:UART1-TX 1000:Reserved 1001:Reserved 1110:PG-EINT12 1111:IO Disable
  [15:12] PG11_SELECT — PG11 Select 0000:Input 0001:Output 0010:I2S1-MCLK 0011:TWI3-SDA 0100:EPHY-25M 0101:CLK-FANOUT1 0110:TCON-TRIG 0111:Reserved 1000:Reserved 1001:Reserved 1110:PG-EINT11 1111:IO Disable
  [11:8] PG10_SELECT — PG10 Select 0000:Input 0001:Output 0010:PWM3 0011:TWI3-SCK 0100:RGMII-RXCK 0101:CLK-FANOUT0 0110:IR-RX 0111:Reserved 1000:Reserved 1001:Reserved 1110:PG-EINT10 1111:IO Disable
  [7:4] PG9_SELECT — PG9 Select. 0000:Input 0001:Output 0010:UART1-CTS 0011:TWI1-SDA 0100:RGMII-RXD3 0101:UART3-RX 0110:Reserved 0111:Reserved 1000:Reserved 1001:Reserved 1110:PG-EINT9 1111:IO Disable
  [3:0] PG8_SELECT — PG8 Select 0000:Input 0001:Output 0010:UART1-RTS 0011:TWI1-SCK 0100:RGMII-RXD2 0101:UART3-TX 0110:Reserved 0111:Reserved 1000:Reserved 1001:Reserved 1110:PG-EINT8 1111:IO Disable
0x128 PG_CFG2 reset 0xFFF
  [11:8] PG18_SELECT — PG18 Select 0000:Input 0001:Output 0010:UART2-RX 0011:TWI3-SDA 0100:PWM6 0101:CLK-FANOUT1 0110:OWA-OUT 0111:UART0-RX 1000:Reserved 1001:Reserved 1110:PG-EINT18 1111:IO Disable
  [7:4] PG17_SELECT — PG17 Select 0000:Input 0001:Output 0010:UART2-TX 0011:TWI3-SCK 0100:PWM7 0101:CLK-FANOUT0 0110:IR-TX 0111:UART0-TX 1000:Reserved 1001:Reserved 1110:PG-EINT17 1111:IO Disable
  [3:0] PG16_SELECT — PG16 Select 0000:Input 0001:Output 0010:IR-RX 0011:TCON-TRIG 0100:PWM5 0101:CLK-FANOUT2 0110: Reserved 0111:LEDC-DO 1000:Reserved 1001:Reserved 1110:PG-EINT16 1111:IO Disable
    7=LEDC_minus_DO (LEDC-DO); 14=PG_minus_EINT16 (PG-EINT16); 15=IO (IO Disable)
0x130 PG_DAT — PG Data Register
  [18:0] PG_DAT — If the port is configured as the input function, the corresponding bit is the pin state. If the port is configured as the output function, the pin state is the same as the corresponding bit. The read bit value is the value set up by software. If the port is configured as a functional pin, the undefined value will be read.
0x134 PG_DRV0 reset 0x11111111 — PG Multi_Driving Register 0
  [all] fields
    {v}=Level_{v} (v=0..3)
  [4n+1:4n] PG{n}_DRV (n=0..7) — PG{n} Multi_Driving Select 00: Level 0 01: Level 1 10: Level 2 11: Level 3
0x138 PG_DRV1 reset 0x11111111 — PG Multi_Driving Register 1
  [all] fields
    {v}=Level_{v} (v=0..3)
  [4n-31:4n-32] PG{n}_DRV (n=8..15) — PG{n} Multi_Driving Select 00: Level 0 01: Level 1 10: Level 2 11: Level 3
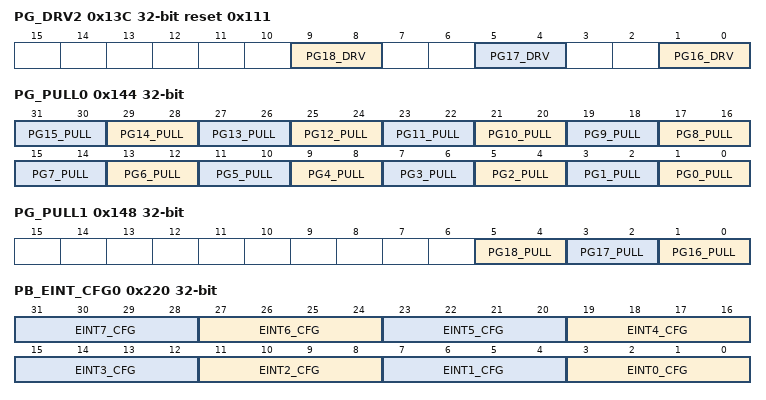
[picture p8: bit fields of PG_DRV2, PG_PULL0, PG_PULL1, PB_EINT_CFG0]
0x13C PG_DRV2 reset 0x111
  [all] fields
    {v}=Level_{v} (v=0..3)
  [9:8] PG18_DRV — PG18 Multi_Driving Select 00: Level 0 01: Level 1 10: Level 2 11: Level 3
  [5:4] PG17_DRV — PG17 Multi_Driving Select 00: Level 0 01: Level 1 10: Level 2 11: Level 3
  [1:0] PG16_DRV — PG16 Multi_Driving Select 00: Level 0 01: Level 1 10: Level 2 11: Level 3
0x144 PG_PULL0 — PG Pull Register 0
  [all] fields
    values as the fields of PB_PULL0
  [2n+1:2n] PG{n}_PULL (n=0..15) — PG{n} Pull_up or down Select. 00: Pull_up/down disable 01: Pull_up 10: Pull_down 11: Reserved
0x148 PG_PULL1
  [all] fields
    values as the fields of PB_PULL0
  [5:4] PG18_PULL — PG18 Pull_up or down Select. 00: Pull_up/down disable 01: Pull_up 10: Pull_down 11: Reserved
  [3:2] PG17_PULL — PG17 Pull_up or down Select. 00: Pull_up/down disable 01: Pull_up 10: Pull_down 11: Reserved
  [1:0] PG16_PULL — PG16 Pull_up or down Select. 00: Pull_up/down disable 01: Pull_up 10: Pull_down 11: Reserved
0x220 PB_EINT_CFG0 — PB External Interrupt Configure Register 0
  [all] fields
    0=Positive_Edge; 1=Negative_Edge; 2=High_Level; 3=Low_Level; 4=Double Edge (Positive/Negative)
  [4n+3:4n] EINT{n}_CFG (n=0..7) — External INT{n} Mode 0x0: Positive Edge 0x1: Negative Edge 0x2: High Level 0x3: Low Level 0x4: Double Edge (Positive/Negative) Others: Reserved
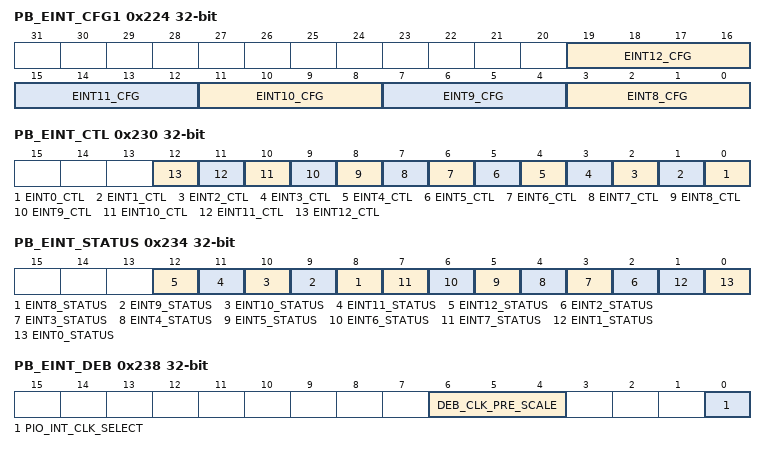
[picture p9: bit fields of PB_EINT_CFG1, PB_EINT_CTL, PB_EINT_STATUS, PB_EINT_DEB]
0x224 PB_EINT_CFG1
  [all] fields
    values as the fields of PB_EINT_CFG0
  [19:16] EINT12_CFG — External INT12 Mode 0x0: Positive Edge 0x1: Negative Edge 0x2: High Level 0x3: Low Level 0x4: Double Edge (Positive/Negative) Others: Reserved
  [15:12] EINT11_CFG — External INT11 Mode 0x0: Positive Edge 0x1: Negative Edge 0x2: High Level 0x3: Low Level 0x4: Double Edge (Positive/Negative) Others: Reserved
  [11:8] EINT10_CFG — External INT10 Mode. 0x0: Positive Edge 0x1: Negative Edge 0x2: High Level 0x3: Low Level 0x4: Double Edge (Positive/Negative) Others: Reserved
  [7:4] EINT9_CFG — External INT9 Mode. 0x0: Positive Edge 0x1: Negative Edge 0x2: High Level 0x3: Low Level 0x4: Double Edge (Positive/Negative) Others: Reserved
  [3:0] EINT8_CFG — External INT8 Mode. 0x0: Positive Edge 0x1: Negative Edge 0x2: High Level 0x3: Low Level 0x4: Double Edge (Positive/Negative) Others: Reserved
0x230 PB_EINT_CTL — PB External Interrupt Control Register
  [all] fields
    0=Disable; 1=Enable
  [n] EINT{n}_CTL (n=0..12) — External INT{n} Enable 0: Disable 1: Enable
0x234 PB_EINT_STATUS — PB External Interrupt Status Register
  [all] fields
    0=No IRQ pending; 1=IRQ pending Write ‘1’ to clear
  [n] EINT{n}_STATUS (n=8..12) — External INT{n} Pending Bit 0: No IRQ pending 1: IRQ pending Write ‘1’ to clear
  [n] EINT{n}_STATUS write-1-clears (n=2..7) — External INT{n} Pending Bit 0: No IRQ pending 1: IRQ pending Write ‘1’ to clear
  [1] EINT1_STATUS — External INT1 Pending Bit 0: No IRQ pending 1: IRQ pending Write ‘1’ to clear
  [0] EINT0_STATUS — External INT0 Pending Bit 0: No IRQ pending 1: IRQ pending Write ‘1’ to clear
0x238 PB_EINT_DEB — PB External Interrupt Debounce Register
  [6:4] DEB_CLK_PRE_SCALE — Debounce Clock Pre_scale n The selected clock source is prescaled by 2^n.
  [0] PIO_INT_CLK_SELECT — PIO Interrupt Clock Select 0: LOSC 32KHz 1: HOSC 24MHz
    0=LOSC (LOSC 32KHz); 1=HOSC (HOSC 24MHz)
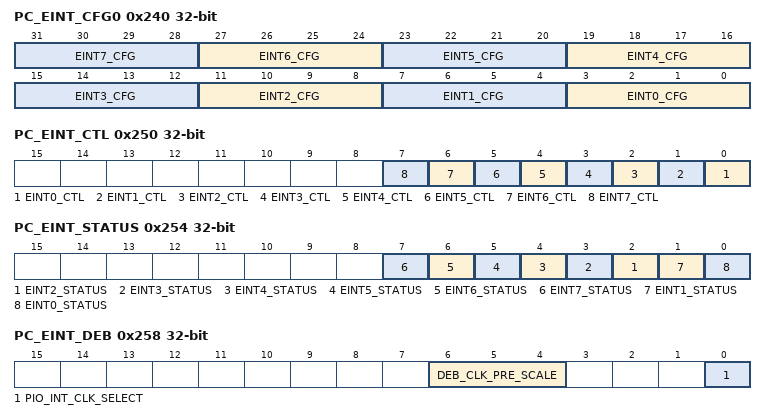
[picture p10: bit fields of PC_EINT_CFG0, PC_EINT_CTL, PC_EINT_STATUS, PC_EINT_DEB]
0x240 PC_EINT_CFG0 — PC External Interrupt Configure Register 0
  fields as PB_EINT_CFG0
0x250 PC_EINT_CTL — PC External Interrupt Control Register
  [all] fields
    0=Disable; 1=Enable
  [n] EINT{n}_CTL (n=0..7) — External INT{n} Enable 0: Disable 1: Enable
0x254 PC_EINT_STATUS — PC External Interrupt Status Register
  [all] fields
    0=No IRQ pending; 1=IRQ pending Write ‘1’ to clear
  [n] EINT{n}_STATUS write-1-clears (n=2..7) — External INT{n} Pending Bit 0: No IRQ pending 1: IRQ pending Write ‘1’ to clear
  [1] EINT1_STATUS — External INT1 Pending Bit 0: No IRQ pending 1: IRQ pending Write ‘1’ to clear
  [0] EINT0_STATUS — External INT0 Pending Bit 0: No IRQ pending 1: IRQ pending Write ‘1’ to clear
0x258 PC_EINT_DEB — PC External Interrupt Debounce Register
  fields as PB_EINT_DEB
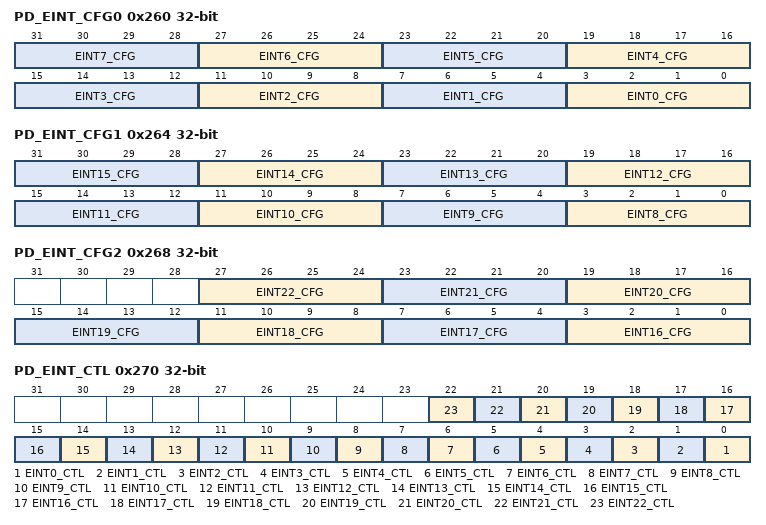
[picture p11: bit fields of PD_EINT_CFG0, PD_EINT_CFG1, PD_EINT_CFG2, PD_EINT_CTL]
0x260 PD_EINT_CFG0 — PD External Interrupt Configure Register 0
  fields as PB_EINT_CFG0
0x264 PD_EINT_CFG1 — PD External Interrupt Configure Register 1
  [all] fields
    values as the fields of PB_EINT_CFG0
  [4n-29:4n-32] EINT{n}_CFG (n=8..15) — External INT{n} Mode 0x0: Positive Edge 0x1: Negative Edge 0x2: High Level 0x3: Low Level 0x4: Double Edge (Positive/Negative) Others: Reserved
0x268 PD_EINT_CFG2 — PD External Interrupt Configure Register 2
  [all] fields
    values as the fields of PB_EINT_CFG0
  [4n-61:4n-64] EINT{n}_CFG (n=16..22) — External INT{n} Mode 0x0: Positive Edge 0x1: Negative Edge 0x2: High Level 0x3: Low Level 0x4: Double Edge (Positive/Negative) Others: Reserved
0x270 PD_EINT_CTL — PD External Interrupt Control Register
  [all] fields
    0=Disable; 1=Enable
  [n] EINT{n}_CTL (n=0..22) — External INT{n} Enable 0: Disable 1: Enable
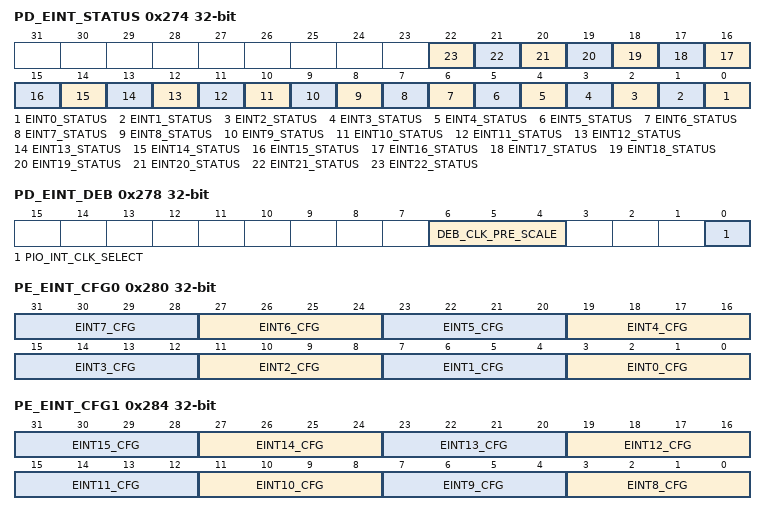
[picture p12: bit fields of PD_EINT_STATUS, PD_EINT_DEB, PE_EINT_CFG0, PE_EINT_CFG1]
0x274 PD_EINT_STATUS — PD External Interrupt Status Register
  [all] fields
    0=No IRQ pending; 1=IRQ pending Write ‘1’ to clear
  [n] EINT{n}_STATUS write-1-clears (n=0..22) — External INT{n} Pending Bit 0: No IRQ pending 1: IRQ pending Write ‘1’ to clear
0x278 PD_EINT_DEB — PD External Interrupt Debounce Register
  fields as PB_EINT_DEB
0x280 PE_EINT_CFG0 — PE External Interrupt Configure Register 0
  fields as PB_EINT_CFG0
0x284 PE_EINT_CFG1 — PE External Interrupt Configure Register 1
  fields as PD_EINT_CFG1
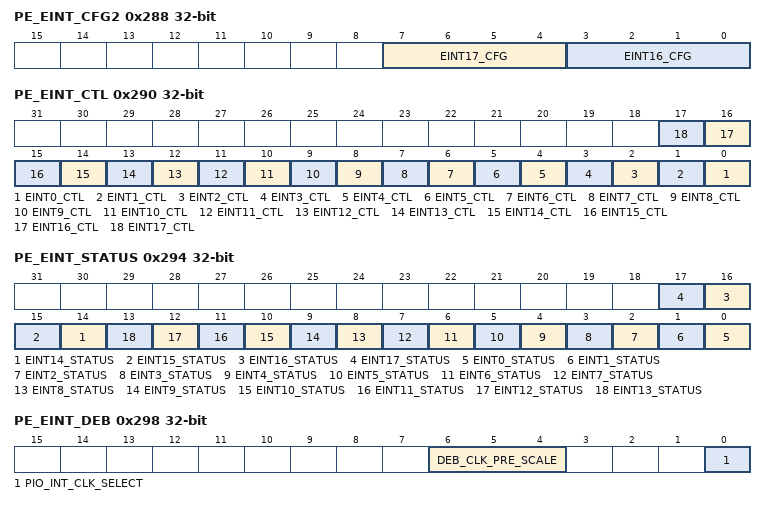
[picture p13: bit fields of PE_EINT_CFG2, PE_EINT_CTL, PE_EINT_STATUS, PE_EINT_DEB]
0x288 PE_EINT_CFG2
  [7:4] EINT17_CFG — External INT17 Mode 0x0: Positive Edge 0x1: Negative Edge 0x2: High Level 0x3: Low Level 0x4: Double Edge (Positive/Negative) Others: Reserved
    values as the fields of PB_EINT_CFG0
  [3:0] EINT16_CFG — External INT16 Mode 0x0: Positive Edge 0x1: Negative Edge 0x2: High Level 0x3: Low Level 0x4: Double Edge (Positive/Negative) Others: Reserved
    values as the fields of PB_EINT_CFG0
0x290 PE_EINT_CTL — PE External Interrupt Control Register
  [all] fields
    0=Disable; 1=Enable
  [n] EINT{n}_CTL (n=0..17) — External INT{n} Enable 0: Disable 1: Enable
0x294 PE_EINT_STATUS — PE External Interrupt Status Register
  [all] fields
    0=No IRQ pending; 1=IRQ pending Write ‘1’ to clear
  [n] EINT{n}_STATUS (n=14..17) — External INT{n} Pending Bit 0: No IRQ pending 1: IRQ pending Write ‘1’ to clear
  [n] EINT{n}_STATUS write-1-clears (n=0..13) — External INT{n} Pending Bit 0: No IRQ pending 1: IRQ pending Write ‘1’ to clear
0x298 PE_EINT_DEB — PE External Interrupt Debounce Register
  fields as PB_EINT_DEB
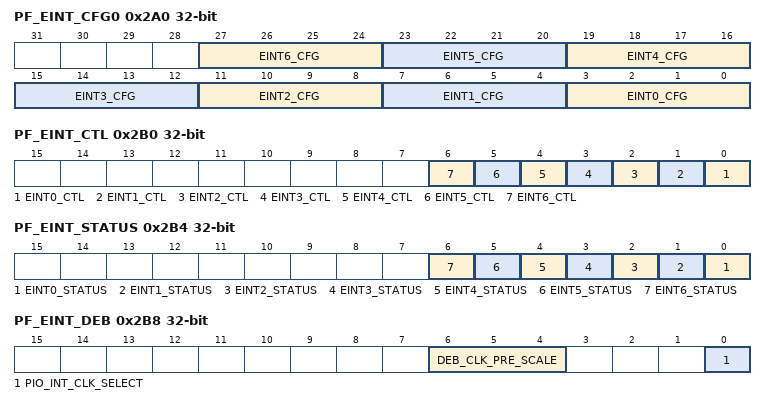
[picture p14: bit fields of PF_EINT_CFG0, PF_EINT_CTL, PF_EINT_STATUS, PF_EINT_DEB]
0x2A0 PF_EINT_CFG0 — PF External Interrupt Configure Register 0
  [all] fields
    values as the fields of PB_EINT_CFG0
  [4n+3:4n] EINT{n}_CFG (n=0..6) — External INT{n} Mode 0x0: Positive Edge 0x1: Negative Edge 0x2: High Level 0x3: Low Level 0x4: Double Edge (Positive/Negative) Others: Reserved
0x2B0 PF_EINT_CTL — PF External Interrupt Control Register
  [all] fields
    0=Disable; 1=Enable
  [n] EINT{n}_CTL (n=0..6) — External INT{n} Enable 0: Disable 1: Enable
0x2B4 PF_EINT_STATUS — PF External Interrupt Status Register
  [all] fields
    0=No IRQ pending; 1=IRQ pending Write ‘1’ to clear
  [n] EINT{n}_STATUS write-1-clears (n=0..6) — External INT{n} Pending Bit 0: No IRQ pending 1: IRQ pending Write ‘1’ to clear
0x2B8 PF_EINT_DEB — PF External Interrupt Debounce Register
  fields as PB_EINT_DEB
0x2C0 PG_EINT_CFG0 — PG External Interrupt Configure Register 0
  fields as PB_EINT_CFG0
0x2C4 PG_EINT_CFG1 — PG External Interrupt Configure Register 1
  fields as PD_EINT_CFG1
0x2C8 PG_EINT_CFG2
  [all] fields
    values as the fields of PB_EINT_CFG0
  [11:8] EINT18_CFG — External INT18 Mode 0x0: Positive Edge 0x1: Negative Edge 0x2: High Level 0x3: Low Level 0x4: Double Edge (Positive/Negative) Others: Reserved
  [7:4] EINT17_CFG — External INT17 Mode 0x0: Positive Edge 0x1: Negative Edge 0x2: High Level 0x3: Low Level 0x4: Double Edge (Positive/Negative) Others: Reserved
  [3:0] EINT16_CFG — External INT16 Mode 0x0: Positive Edge 0x1: Negative Edge 0x2: High Level 0x3: Low Level 0x4: Double Edge (Positive/Negative) Others: Reserved
0x2D0 PG_EINT_CTL — PG External Interrupt Control Register
  [all] fields
    0=Disable; 1=Enable
  [n] EINT{n}_CTL (n=0..18) — External INT{n} Enable 0: Disable 1: Enable
0x2D4 PG_EINT_STATUS — PG External Interrupt Status Register
  [all] fields
    0=No IRQ pending; 1=IRQ pending Write ‘1’ to clear
  [18] EINT18_STATUS — External INT18 Pending Bit 0: No IRQ pending 1: IRQ pending Write ‘1’ to clear
  [17] EINT17_STATUS — External INT17 Pending Bit 0: No IRQ pending 1: IRQ pending Write ‘1’ to clear
  [16] EINT16_STATUS — External INT16 Pending Bit 0: No IRQ pending 1: IRQ pending Write ‘1’ to clear
  [n] EINT{n}_STATUS write-1-clears (n=0..15) — External INT{n} Pending Bit 0: No IRQ pending 1: IRQ pending Write ‘1’ to clear
0x2D8 PG_EINT_DEB — PG External Interrupt Debounce Register
  fields as PB_EINT_DEB
0x340 PIO_POW_MOD_SEL — PIO Group Withstand Voltage Mode Select Register
  [12] VCCIO_PWR_MOD_SEL — VCC_IO POWER MODE Select 0: 3.3 V 1: 1.8 V
    0=_3_point_3_V (3.3 V); 1=_1_point_8_V (1.8 V)
  [6] PG_PWR_MOD_SEL — PG_POWER MODE Select 0: 3.3 V 1: 1.8 V If PG_Port Power Source selects VCC_IO, this bit is invalid.
    0=_3_point_3_V (3.3 V); 1=_1_point_8_V (1.8 V If PG_Port Power Source selects VCC_IO, this bit is invalid.)
  [5] PF_PWR_MOD_SEL — PF_POWER MODE Select 0: 3.3 V 1: 1.8 V If PF_Port Power Source selects VCC_IO, this bit is invalid.
    0=_3_point_3_V (3.3 V); 1=_1_point_8_V (1.8 V If PF_Port Power Source selects VCC_IO, this bit is invalid.)
  [4] PE_PWR_MOD_SEL — PE_POWER MODE Select 0: 3.3 V 1: 1.8 V If PE_Port Power Source selects VCC_IO, this bit is invalid.
    0=_3_point_3_V (3.3 V); 1=_1_point_8_V (1.8 V If PE_Port Power Source selects VCC_IO, this bit is invalid.)
  [3] PD_PWR_MOD_SEL — PD_POWER MODE Select 0: 3.3 V 1: 1.8 V If PD_Port Power Source selects VCC_IO, this bit is invalid.
    0=_3_point_3_V (3.3 V); 1=_1_point_8_V (1.8 V If PD_Port Power Source selects VCC_IO, this bit is invalid.)
  [2] PC_PWR_MOD_SEL — PC_POWER MODE Select 0: 3.3 V 1: 1.8 V If PC_Port Power Source selects VCC_IO, this bit is invalid.
    0=_3_point_3_V (3.3 V); 1=_1_point_8_V (1.8 V If PC_Port Power Source selects VCC_IO, this bit is invalid.)
0x344 PIO_POW_MS_CTL — PIO Group Withstand Voltage Mode Select Control Register
  [all] fields
    0=Enable; 1=Disable
  [12] VCCIO_WS_VOL_MOD_SEL — VCC_IO Withstand Voltage Mode Select Control 0: Enable 1: Disable
  [6] VCC_PG_WS_VOL_MOD_SEL — VCC_PG Withstand Voltage Mode Select Control 0: Enable 1: Disable
  [5] VCC_PF_WS_VOL_MOD_SEL — VCC_PF Withstand Voltage Mode Select Control 0: Enable 1: Disable
  [4] VCC_PE_WS_VOL_MOD_SEL — VCC_PE Withstand Voltage Mode Select Control 0: Enable 1: Disable
  [3] VCC_PD_WS_VOL_MOD_SEL — VCC_PD Withstand Voltage Mode Select Control 0: Enable 1: Disable
  [2] VCC_PC_WS_VOL_MOD_SEL — VCC_PC Withstand Voltage Mode Select Control 0: Enable 1: Disable
0x348 PIO_POW_VAL — PIO Group Power Value Register
  [16] VCCIO_PWR_VAL ro — VCC_IO Power Value
  [6] PG_PWR_VAL ro — PG_Port Power Value If PG_Port power source selects VCC_IO, this bit is invalid.
  [5] PF_PWR_VAL ro — PF_Port Power Value If PF_Port power source selects VCC_IO, this bit is invalid.
  [4] PE_PWR_VAL ro — PE_Port Power Value If PE_Port power source selects VCC_IO, this bit is invalid.
  [3] PD_PWR_VAL ro — PD_Port Power Value If PD_Port power source selects VCC_IO, this bit is invalid.
  [2] PC_PWR_VAL ro — PC_Port Power Value If PC_Port power source selects VCC_IO, this bit is invalid.
0x350 PIO_POW_VOL_SEL_CTL reset 0x1 — PIO Group Power Voltage Select Control Register
  [0] VCC-PF — Power Voltage Select Control 0: 1.8 V 1: 3.3 V
    0=_1_point_8_V (1.8 V); 1=_3_point_3_V (3.3 V)
